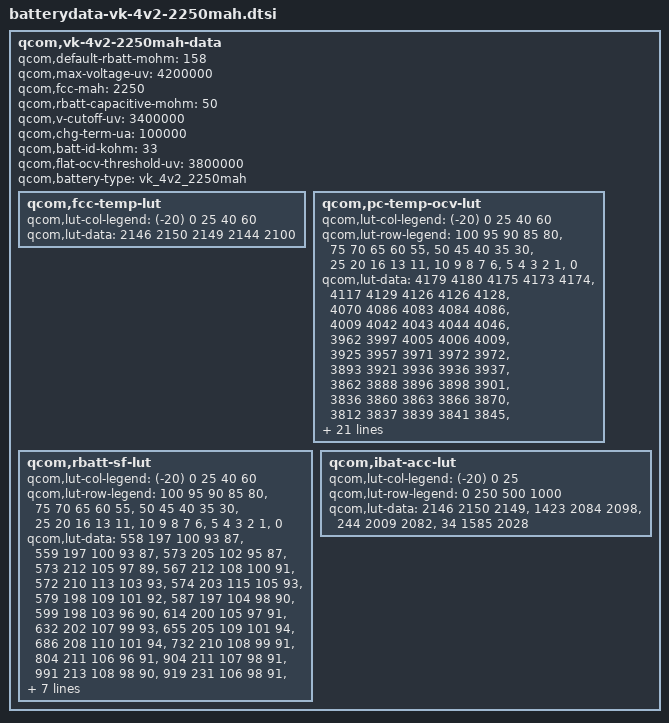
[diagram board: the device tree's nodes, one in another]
/* Copyright (c) 2014, The Linux Foundation. All rights reserved.
 *
 * This program is free software; you can redistribute it and/or modify
 * it under the terms of the GNU General Public License version 2 and
 * only version 2 as published by the Free Software Foundation.
 *
 * This program is distributed in the hope that it will be useful,
 * but WITHOUT ANY WARRANTY; without even the implied warranty of
 * MERCHANTABILITY or FITNESS FOR A PARTICULAR PURPOSE.  See the
 * GNU General Public License for more details.
 */

qcom,vk-4v2-2250mah-data {
	qcom,default-rbatt-mohm = <158>;
	qcom,max-voltage-uv = <4200000>;
	qcom,fcc-mah = <2250>;
	qcom,rbatt-capacitive-mohm = <50>;
	qcom,v-cutoff-uv = <3400000>;
	qcom,chg-term-ua = <100000>;
	qcom,batt-id-kohm = <33>;
	qcom,flat-ocv-threshold-uv = <3800000>;
	qcom,battery-type = "vk_4v2_2250mah";

	qcom,fcc-temp-lut {
		qcom,lut-col-legend = <(-20) 0 25 40 60>;
		qcom,lut-data = <2146 2150 2149 2144 2100>;
	};

	qcom,pc-temp-ocv-lut {
		qcom,lut-col-legend = <(-20) 0 25 40 60>;
		qcom,lut-row-legend = <100 95 90 85 80>,
				<75 70 65 60 55>,
				<50 45 40 35 30>,
				<25 20 16 13 11>,
				<10 9 8 7 6>,
				<5 4 3 2 1 >,
				<0>;
		qcom,lut-data = <4179 4180 4175 4173 4174>,
				<4117 4129 4126 4126 4128>,
				<4070 4086 4083 4084 4086>,
				<4009 4042 4043 4044 4046>,
				<3962 3997 4005 4006 4009>,
				<3925 3957 3971 3972 3972>,
				<3893 3921 3936 3936 3937>,
				<3862 3888 3896 3898 3901>,
				<3836 3860 3863 3866 3870>,
				<3812 3837 3839 3841 3845>,
				<3792 3817 3820 3822 3825>,
				<3776 3799 3803 3805 3807>,
				<3764 3784 3789 3790 3789>,
				<3753 3771 3775 3773 3769>,
				<3742 3758 3758 3753 3743>,
				<3729 3743 3740 3733 3721>,
				<3712 3725 3722 3714 3701>,
				<3694 3709 3704 3696 3681>,
				<3672 3701 3689 3682 3669>,
				<3654 3693 3683 3675 3665>,
				<3642 3688 3681 3673 3663>,
				<3630 3684 3679 3671 3652>,
				<3613 3669 3671 3661 3642>,
				<3595 3655 3663 3648 3631>,
				<3573 3631 3639 3623 3600>,
				<3545 3600 3602 3586 3564>,
				<3509 3560 3557 3538 3519>,
				<3461 3506 3499 3479 3461>,
				<3396 3433 3422 3401 3386>,
	                        <3291 3318 3312 3290 3271>,
                                <3000 3000 3000 3000 3000>;
    };
	qcom,rbatt-sf-lut {
		qcom,lut-col-legend = <(-20) 0 25 40 60>;
		qcom,lut-row-legend = <100 95 90 85 80>,
				<75 70 65 60 55>,
				<50 45 40 35 30>,
				<25 20 16 13 11>,
				<10 9 8 7 6>,
				<5 4 3 2 1 >,
				<0>;
		qcom,lut-data = < 558 197 100 93 87>,
                < 559 197 100 93 87>,
                < 573 205 102 95 87>,
                < 573 212 105 97 89>,
                < 567 212 108 100 91>,
                < 572 210 113 103 93>,
                < 574 203 115 105 93>,
                < 579 198 109 101 92>,
                < 587 197 104 98 90>,
                < 599 198 103 96 90>,
                < 614 200 105 97 91>,
                < 632 202 107 99 93>,
                < 655 205 109 101 94>,
                < 686 208 110 101 94>,
                < 732 210 108 99 91>,
                < 804 211 106 96 91>,
                < 904 211 107 98 91>,
                < 991 213 108 98 90>,
                < 919 231 106 98 91>,
                < 1025 248 108 99 93>,
                < 1100 260 110 101 94>,
                < 1181 272 113 103 94>,
                < 1265 272 114 103 94>,
                < 1347 273 116 101 94>,
                < 1437 246 111 100 94>,
                < 1623 244 109 100 94>,
                < 1991 249 111 100 95>,
                < 2601 261 113 103 97>,
                < 3668 280 119 113 105>,
                < 6050 346 148 154 122>,
                < 182065 55029 44641 90608 69318>;		
	};

	qcom,ibat-acc-lut {
		qcom,lut-col-legend = <(-20) 0 25>;
		qcom,lut-row-legend = <0 250 500 1000>;
		qcom,lut-data = <2146 2150 2149>,
				<1423 2084 2098>,
				<244 2009 2082>,
				<34 1585 2028>;
	};
};
